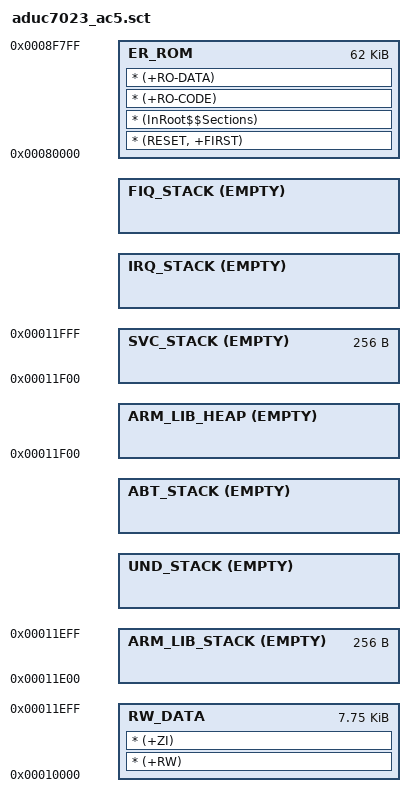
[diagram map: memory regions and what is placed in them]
#! armcc -E
; command above MUST be in first line (no comment above!)

/*-----------------------------------------------------------------------------
;             <<< Use Configuration Wizard in Context Menu >>>
 -----------------------------------------------------------------------------*/

/*---------------------- Flash Configuration ----------------------------------
;  <h> Flash Configuration
;    <o0> Flash Base Address <0x0-0xFFFFFFFF:8>
;    <o1> Flash Size (in Bytes) <0x0-0xFFFFFFFF:8>
;  </h>
 -----------------------------------------------------------------------------*/
#define __ROM_BASE        0x00080000
#define __ROM_SIZE        0x0000F800

/*--------------------- RAM Configuration -----------------------------------
; <h> RAM Configuration
;   <o0> RAM Base Address    <0x0-0xFFFFFFFF:8>
;   <o1> RAM Total Size (in Bytes) <0x0-0xFFFFFFFF:8>
;   <h> Stack / Heap Configuration
;     <o2>  Stack Size (in Bytes) <0x0-0xFFFFFFFF:8>
;     <o3>  Heap Size (in Bytes) <0x0-0xFFFFFFFF:8>
;     <h> Exceptional Modes
;       <o4> UND Stack Size (in Bytes) <0x0-0xFFFFFFFF:8>
;       <o5> ABT Stack Size (in Bytes) <0x0-0xFFFFFFFF:8>
;       <o6> SVC Stack Size (in Bytes) <0x0-0xFFFFFFFF:8>
;       <o7> IRQ Stack Size (in Bytes) <0x0-0xFFFFFFFF:8>
;       <o8> FIQ Stack Size (in Bytes) <0x0-0xFFFFFFFF:8>
;     </h>
;   </h>
; </h>
 *----------------------------------------------------------------------------*/
#define __RAM_BASE        0x00010000
#define __RAM_SIZE        0x00002000

#define __STACK_SIZE      0x00000100
#define __HEAP_SIZE       0x00000000

#define __UND_STACK_SIZE  0x00000000
#define __ABT_STACK_SIZE  0x00000000
#define __SVC_STACK_SIZE  0x00000100
#define __IRQ_STACK_SIZE  0x00000000
#define __FIQ_STACK_SIZE  0x00000000

/*-----------------------------------------------------------------------------
;                   <<< end of configuration section >>>                    
 -----------------------------------------------------------------------------*/

#define __RW_DATA_SIZE    (__RAM_SIZE - __STACK_SIZE - __HEAP_SIZE)


LR_ROM __ROM_BASE __ROM_SIZE  { ; load region size_region
  ER_ROM __ROM_BASE __ROM_SIZE  ; load address = execution address
  {
      * (RESET, +FIRST)         ; Vector table and other startup code
      * (InRoot$$Sections)      ; All (library) code that must be in a root region
      * (+RO-CODE)              ; Application RO code (.text)
      * (+RO-DATA)              ; Application RO data (.constdata)
  }
  
  RW_DATA __RAM_BASE __RW_DATA_SIZE
  { 
    * (+RW)                     ; Application RW data (.data)
    * (+ZI)                     ; Application ZI data (.bss)
  }
    
  ARM_LIB_HEAP  (__RAM_BASE
                +__RW_DATA_SIZE)    EMPTY __HEAP_SIZE        ; Heap region growing up
  { }
    
  ARM_LIB_STACK (__RAM_BASE
                +__RAM_SIZE       
                -__FIQ_STACK_SIZE
                -__IRQ_STACK_SIZE
                -__SVC_STACK_SIZE
                -__ABT_STACK_SIZE
                -__UND_STACK_SIZE) EMPTY -__STACK_SIZE      ; Stack region growing down
  { }              
                
  UND_STACK     (__RAM_BASE
                +__RAM_SIZE
                -__FIQ_STACK_SIZE
                -__IRQ_STACK_SIZE
                -__SVC_STACK_SIZE
                -__ABT_STACK_SIZE) EMPTY -__UND_STACK_SIZE  ; UND mode stack
  { }
  
  ABT_STACK     (__RAM_BASE
                +__RAM_SIZE
                -__FIQ_STACK_SIZE
                -__IRQ_STACK_SIZE
                -__SVC_STACK_SIZE) EMPTY -__ABT_STACK_SIZE  ; ABT mode stack
  { }
  
  SVC_STACK     (__RAM_BASE
                +__RAM_SIZE
                -__FIQ_STACK_SIZE
                -__IRQ_STACK_SIZE) EMPTY -__SVC_STACK_SIZE  ; SVC mode stack
  { }  
  
  IRQ_STACK     (__RAM_BASE
                +__RAM_SIZE
                -__FIQ_STACK_SIZE) EMPTY -__IRQ_STACK_SIZE  ; IRQ mode stack
  { }  
  
  FIQ_STACK     (__RAM_BASE
                +__RAM_SIZE)       EMPTY -__FIQ_STACK_SIZE  ; FIQ mode stack
  { }
}
